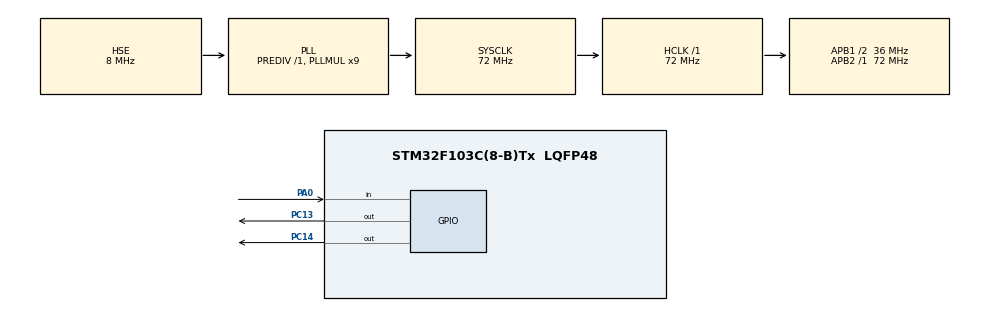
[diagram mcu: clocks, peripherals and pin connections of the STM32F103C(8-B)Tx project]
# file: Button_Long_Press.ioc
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Mcu.Family=STM32F1
Mcu.Name=STM32F103C(8-B)Tx
Mcu.Package=LQFP48
NVIC.PriorityGroup=NVIC_PRIORITYGROUP_4
PA0-WKUP.GPIO_PuPd=GPIO_PULLUP
PA0-WKUP.Signal=GPIO_Input
PA13.Mode=Serial_Wire
PA13.Signal=SYS_JTMS-SWDIO
PA14.Mode=Serial_Wire
PA14.Signal=SYS_JTCK-SWCLK
PC13-TAMPER-RTC.Signal=GPIO_Output
PC14-OSC32_IN.Signal=GPIO_Output
PD0-OSC_IN.Mode=HSE-External-Oscillator
PD0-OSC_IN.Signal=RCC_OSC_IN
PD1-OSC_OUT.Mode=HSE-External-Oscillator
PD1-OSC_OUT.Signal=RCC_OSC_OUT
ProjectManager.HeapSize=0x200
ProjectManager.StackSize=0x400
ProjectManager.TargetToolchain=MDK-ARM V5.32
RCC.AHBFreq_Value=72000000
RCC.APB1CLKDivider=RCC_HCLK_DIV2
RCC.APB1Freq_Value=36000000
RCC.APB1TimFreq_Value=72000000
RCC.APB2Freq_Value=72000000
RCC.APB2TimFreq_Value=72000000
RCC.HCLKFreq_Value=72000000
RCC.PLLMUL=RCC_PLL_MUL9
RCC.PLLSourceVirtual=RCC_PLLSOURCE_HSE
RCC.SYSCLKFreq_VALUE=72000000
RCC.SYSCLKSource=RCC_SYSCLKSOURCE_PLLCLK
RCC.USBFreq_Value=72000000
board=custom

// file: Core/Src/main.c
/* USER CODE BEGIN Header */
/**
  ******************************************************************************
  * @file           : main.c
  * @brief          : Main program body
  ******************************************************************************
  * @attention
  *
  * Copyright (c) 2022 STMicroelectronics.
  * All rights reserved.
  *
  * This software is licensed under terms that can be found in the LICENSE file
  * in the root directory of this software component.
  * If no LICENSE file comes with this software, it is provided AS-IS.
  *
  ******************************************************************************
  */
/* USER CODE END Header */
#include "main.h"

void SystemClock_Config(void);
static void MX_GPIO_Init(void);

/* USER CODE BEGIN 0 */
typedef enum
{
	LED_BLINK_NONE,
	LED_BLINK_LED1,
	LED_BLINK_LED2,
	LED_BLINK_ALL,
}State_led_t;
State_led_t state_led;
void blink_led_1()
{
	static uint32_t t=0;
	static uint8_t sta=0;
	if(HAL_GetTick() - t>=500)
	{
		sta=!sta;
		HAL_GPIO_WritePin(GPIOC, GPIO_PIN_13,(GPIO_PinState)sta);
		t=HAL_GetTick();
	}
}
void blink_led_2()
{
	static uint32_t t=0;
	static uint8_t sta=0;
	if(HAL_GetTick() - t>=100)
	{
		sta=!sta;
		HAL_GPIO_WritePin(GPIOC, GPIO_PIN_14,(GPIO_PinState)sta);
		t=HAL_GetTick();
	}
}
	static uint8_t ispress=0, islongpress=0;
	static uint32_t timePress=0;
void check_button()
{
	if(HAL_GPIO_ReadPin(GPIOA, GPIO_PIN_0)==0)
		{
			if(ispress==0)
			{
				HAL_Delay(20);
				if(HAL_GPIO_ReadPin(GPIOA, GPIO_PIN_0)==0)
				{
					timePress= HAL_GetTick();
					ispress=1;
				}
			}
			if((islongpress==0)&&(HAL_GetTick()-timePress >=3000) )
			{
				islongpress=1;
				state_led=LED_BLINK_NONE;
			}
		}
	else
		{
			if(islongpress)
				{
					islongpress=0;
					timePress=HAL_GetTick();
				}
			else if(ispress==1)
			{
				if(state_led==LED_BLINK_ALL)
				{
					state_led=LED_BLINK_LED1;
				}
				else if(state_led==LED_BLINK_LED1)
				{
					state_led= LED_BLINK_LED2;
				}
				else if(state_led==LED_BLINK_LED2)
				{
					state_led=LED_BLINK_ALL;
				}
				else if(state_led==LED_BLINK_NONE)
				{
					state_led=LED_BLINK_ALL;
				}
			}
			ispress=0;
		}
}
/* USER CODE END 0 */

int main(void)
{

  /* MCU Configuration--------------------------------------------------------*/

  /* Reset of all peripherals, Initializes the Flash interface and the Systick. */
  HAL_Init();

  /* Configure the system clock */
  SystemClock_Config();

  /* Initialize all configured peripherals */
  MX_GPIO_Init();
  /* USER CODE BEGIN 2 */
	state_led=LED_BLINK_ALL;

  /* USER CODE END 2 */

  /* Infinite loop */
  while (1)
  {

    /* USER CODE BEGIN 3 */
		check_button();
		switch(state_led)
		{
			case LED_BLINK_LED1:
				blink_led_1();
				HAL_GPIO_WritePin(GPIOC, GPIO_PIN_14,0);
				break;
			case LED_BLINK_LED2:
				blink_led_2();
				HAL_GPIO_WritePin(GPIOC, GPIO_PIN_13,1);
				break;
			case LED_BLINK_ALL:
				blink_led_1();
				blink_led_2();
				break;
			case LED_BLINK_NONE:
				HAL_GPIO_WritePin(GPIOC, GPIO_PIN_14,0);
				HAL_GPIO_WritePin(GPIOC, GPIO_PIN_13,1);
				break;
		}
  }
  /* USER CODE END 3 */
}

void SystemClock_Config(void)
{
  RCC_OscInitTypeDef RCC_OscInitStruct = {0};
  RCC_ClkInitTypeDef RCC_ClkInitStruct = {0};

  /** Initializes the RCC Oscillators according to the specified parameters
  * in the RCC_OscInitTypeDef structure.
  */
  RCC_OscInitStruct.OscillatorType = RCC_OSCILLATORTYPE_HSE;
  RCC_OscInitStruct.HSEState = RCC_HSE_ON;
  RCC_OscInitStruct.HSEPredivValue = RCC_HSE_PREDIV_DIV1;
  RCC_OscInitStruct.HSIState = RCC_HSI_ON;
  RCC_OscInitStruct.PLL.PLLState = RCC_PLL_ON;
  RCC_OscInitStruct.PLL.PLLSource = RCC_PLLSOURCE_HSE;
  RCC_OscInitStruct.PLL.PLLMUL = RCC_PLL_MUL9;
  if (HAL_RCC_OscConfig(&RCC_OscInitStruct) != HAL_OK)
  {
    Error_Handler();
  }

  /** Initializes the CPU, AHB and APB buses clocks
  */
  RCC_ClkInitStruct.ClockType = RCC_CLOCKTYPE_HCLK|RCC_CLOCKTYPE_SYSCLK
                              |RCC_CLOCKTYPE_PCLK1|RCC_CLOCKTYPE_PCLK2;
  RCC_ClkInitStruct.SYSCLKSource = RCC_SYSCLKSOURCE_PLLCLK;
  RCC_ClkInitStruct.AHBCLKDivider = RCC_SYSCLK_DIV1;
  RCC_ClkInitStruct.APB1CLKDivider = RCC_HCLK_DIV2;
  RCC_ClkInitStruct.APB2CLKDivider = RCC_HCLK_DIV1;

  if (HAL_RCC_ClockConfig(&RCC_ClkInitStruct, FLASH_LATENCY_2) != HAL_OK)
  {
    Error_Handler();
  }
}

static void MX_GPIO_Init(void)
{
  GPIO_InitTypeDef GPIO_InitStruct = {0};

  /* GPIO Ports Clock Enable */
  __HAL_RCC_GPIOC_CLK_ENABLE();
  __HAL_RCC_GPIOD_CLK_ENABLE();
  __HAL_RCC_GPIOA_CLK_ENABLE();

  /*Configure GPIO pin Output Level */
  HAL_GPIO_WritePin(GPIOC, GPIO_PIN_13|GPIO_PIN_14, GPIO_PIN_RESET);

  /*Configure GPIO pins : PC13 PC14 */
  GPIO_InitStruct.Pin = GPIO_PIN_13|GPIO_PIN_14;
  GPIO_InitStruct.Mode = GPIO_MODE_OUTPUT_PP;
  GPIO_InitStruct.Pull = GPIO_NOPULL;
  GPIO_InitStruct.Speed = GPIO_SPEED_FREQ_LOW;
  HAL_GPIO_Init(GPIOC, &GPIO_InitStruct);

  /*Configure GPIO pin : PA0 */
  GPIO_InitStruct.Pin = GPIO_PIN_0;
  GPIO_InitStruct.Mode = GPIO_MODE_INPUT;
  GPIO_InitStruct.Pull = GPIO_PULLUP;
  HAL_GPIO_Init(GPIOA, &GPIO_InitStruct);

}

void Error_Handler(void)
{
  __disable_irq();
  while (1)
  {
  }
}
